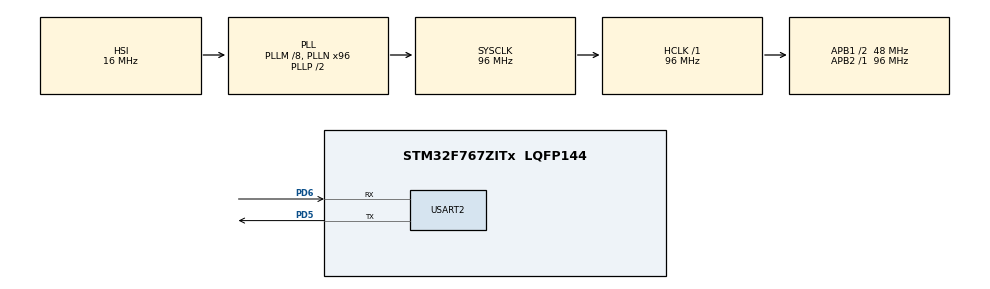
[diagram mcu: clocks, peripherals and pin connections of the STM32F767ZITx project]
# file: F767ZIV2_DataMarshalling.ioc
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FREERTOS.Queues01=msgQueue,16,uint16_t,0,Dynamic,NULL,NULL
FREERTOS.Tasks01=instTask,24,128,instTaskEndPnt,Default,NULL,Dynamic,NULL,NULL;commTask,24,128,commTaskEndPnt,Default,NULL,Dynamic,NULL,NULL
FREERTOS.configUSE_NEWLIB_REENTRANT=1
Mcu.Family=STM32F7
Mcu.Name=STM32F767ZITx
Mcu.Package=LQFP144
NVIC.PriorityGroup=NVIC_PRIORITYGROUP_4
NVIC.TIM1_UP_TIM10_IRQn=true\:15\:0\:false\:false\:true\:false\:false\:true\:true
NVIC.TimeBase=TIM1_UP_TIM10_IRQn
NVIC.TimeBaseIP=TIM1
NVIC.USART2_IRQn=true\:5\:0\:false\:false\:true\:true\:true\:true\:true
PA13.Mode=Serial_Wire
PA13.Signal=SYS_JTMS-SWDIO
PA14.Mode=Serial_Wire
PA14.Signal=SYS_JTCK-SWCLK
PD5.Mode=Asynchronous
PD5.Signal=USART2_TX
PD6.Mode=Asynchronous
PD6.Signal=USART2_RX
PH0/OSC_IN.Mode=HSE-External-Oscillator
PH0/OSC_IN.Signal=RCC_OSC_IN
PH1/OSC_OUT.Mode=HSE-External-Oscillator
PH1/OSC_OUT.Signal=RCC_OSC_OUT
ProjectManager.HeapSize=0x200
ProjectManager.StackSize=0x400
ProjectManager.TargetToolchain=STM32CubeIDE
RCC.AHBFreq_Value=96000000
RCC.APB1CLKDivider=RCC_HCLK_DIV2
RCC.APB1Freq_Value=48000000
RCC.APB1TimFreq_Value=96000000
RCC.APB2Freq_Value=96000000
RCC.APB2TimFreq_Value=96000000
RCC.CortexFreq_Value=96000000
RCC.HCLKFreq_Value=96000000
RCC.HSE_VALUE=25000000
RCC.HSI_VALUE=16000000
RCC.LSE_VALUE=32768
RCC.PLLM=8
RCC.PLLN=96
RCC.SYSCLKFreq_VALUE=96000000
RCC.SYSCLKSource=RCC_SYSCLKSOURCE_PLLCLK
RCC.USBFreq_Value=96000000
RCC.VCOOutputFreq_Value=192000000
USART2.VirtualMode-Asynchronous=VM_ASYNC
VP_FREERTOS_VS_CMSIS_V2.Mode=CMSIS_V2
VP_SYS_VS_tim1.Mode=TIM1
board=custom

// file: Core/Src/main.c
/* USER CODE BEGIN Header */
/**
  ******************************************************************************
  * @file           : main.c
  * @brief          : Main program body
  ******************************************************************************
  * @attention
  *
  * Copyright (c) 2022 STMicroelectronics.
  * All rights reserved.
  *
  * This software is licensed under terms that can be found in the LICENSE file
  * in the root directory of this software component.
  * If no LICENSE file comes with this software, it is provided AS-IS.
  *
  ******************************************************************************
  */
/* USER CODE END Header */
#include "main.h"
#include "cmsis_os.h"

/* USER CODE BEGIN Includes */
#include <time.h>
#include <stdlib.h>
#include <stdio.h>
#include <math.h>
#include <string.h>
#define BUFF_SZ 5
/* USER CODE END Includes */

/* USER CODE BEGIN PTD */
typedef struct {                                // object data type
	uint8_t value;
	uint8_t id;
} SENSOR_MSG_t;
/* USER CODE END PTD */

UART_HandleTypeDef huart2;

/* Definitions for instTask */
osThreadId_t instTaskHandle;
const osThreadAttr_t instTask_attributes = {
  .name = "instTask",
  .stack_size = 128 * 4,
  .priority = (osPriority_t) osPriorityNormal,
};
/* Definitions for commTask */
osThreadId_t commTaskHandle;
const osThreadAttr_t commTask_attributes = {
  .name = "commTask",
  .stack_size = 128 * 4,
  .priority = (osPriority_t) osPriorityNormal,
};
/* Definitions for msgQueue */
osMessageQueueId_t msgQueueHandle;
const osMessageQueueAttr_t msgQueue_attributes = {
  .name = "msgQueue"
};

void SystemClock_Config(void);
static void MX_GPIO_Init(void);
static void MX_USART2_UART_Init(void);
void instTaskEndPnt(void *argument);
void commTaskEndPnt(void *argument);

int main(void)
{

  /* MCU Configuration--------------------------------------------------------*/

  /* Reset of all peripherals, Initializes the Flash interface and the Systick. */
  HAL_Init();

  /* Configure the system clock */
  SystemClock_Config();

  /* Initialize all configured peripherals */
  MX_GPIO_Init();
  MX_USART2_UART_Init();
  /* USER CODE BEGIN 2 */
  uint8_t msg[BUFF_SZ]     = {0};
  HAL_UART_Receive_IT(&huart2, msg, sizeof(msg));
  /* USER CODE END 2 */

  /* Init scheduler */
  osKernelInitialize();

  /* Create the queue(s) */
  /* creation of msgQueue */
  msgQueueHandle = osMessageQueueNew (16, sizeof(uint16_t), &msgQueue_attributes);

  /* Create the thread(s) */
  /* creation of instTask */
  instTaskHandle = osThreadNew(instTaskEndPnt, NULL, &instTask_attributes);

  /* creation of commTask */
  commTaskHandle = osThreadNew(commTaskEndPnt, NULL, &commTask_attributes);

  /* Start scheduler */
  osKernelStart();

  /* We should never get here as control is now taken by the scheduler */
  /* Infinite loop */
  while (1)
  {

  }
}

void SystemClock_Config(void)
{
  RCC_OscInitTypeDef RCC_OscInitStruct = {0};
  RCC_ClkInitTypeDef RCC_ClkInitStruct = {0};

  /** Configure the main internal regulator output voltage
  */
  __HAL_RCC_PWR_CLK_ENABLE();
  __HAL_PWR_VOLTAGESCALING_CONFIG(PWR_REGULATOR_VOLTAGE_SCALE3);

  /** Initializes the RCC Oscillators according to the specified parameters
  * in the RCC_OscInitTypeDef structure.
  */
  RCC_OscInitStruct.OscillatorType = RCC_OSCILLATORTYPE_HSI;
  RCC_OscInitStruct.HSIState = RCC_HSI_ON;
  RCC_OscInitStruct.HSICalibrationValue = RCC_HSICALIBRATION_DEFAULT;
  RCC_OscInitStruct.PLL.PLLState = RCC_PLL_ON;
  RCC_OscInitStruct.PLL.PLLSource = RCC_PLLSOURCE_HSI;
  RCC_OscInitStruct.PLL.PLLM = 8;
  RCC_OscInitStruct.PLL.PLLN = 96;
  RCC_OscInitStruct.PLL.PLLP = RCC_PLLP_DIV2;
  RCC_OscInitStruct.PLL.PLLQ = 2;
  RCC_OscInitStruct.PLL.PLLR = 2;
  if (HAL_RCC_OscConfig(&RCC_OscInitStruct) != HAL_OK)
  {
    Error_Handler();
  }

  /** Activate the Over-Drive mode
  */
  if (HAL_PWREx_EnableOverDrive() != HAL_OK)
  {
    Error_Handler();
  }

  /** Initializes the CPU, AHB and APB buses clocks
  */
  RCC_ClkInitStruct.ClockType = RCC_CLOCKTYPE_HCLK|RCC_CLOCKTYPE_SYSCLK
                              |RCC_CLOCKTYPE_PCLK1|RCC_CLOCKTYPE_PCLK2;
  RCC_ClkInitStruct.SYSCLKSource = RCC_SYSCLKSOURCE_PLLCLK;
  RCC_ClkInitStruct.AHBCLKDivider = RCC_SYSCLK_DIV1;
  RCC_ClkInitStruct.APB1CLKDivider = RCC_HCLK_DIV2;
  RCC_ClkInitStruct.APB2CLKDivider = RCC_HCLK_DIV1;

  if (HAL_RCC_ClockConfig(&RCC_ClkInitStruct, FLASH_LATENCY_3) != HAL_OK)
  {
    Error_Handler();
  }
}

static void MX_USART2_UART_Init(void)
{

  huart2.Instance = USART2;
  huart2.Init.BaudRate = 115200;
  huart2.Init.WordLength = UART_WORDLENGTH_8B;
  huart2.Init.StopBits = UART_STOPBITS_1;
  huart2.Init.Parity = UART_PARITY_NONE;
  huart2.Init.Mode = UART_MODE_TX_RX;
  huart2.Init.HwFlowCtl = UART_HWCONTROL_NONE;
  huart2.Init.OverSampling = UART_OVERSAMPLING_16;
  huart2.Init.OneBitSampling = UART_ONE_BIT_SAMPLE_DISABLE;
  huart2.AdvancedInit.AdvFeatureInit = UART_ADVFEATURE_NO_INIT;
  if (HAL_UART_Init(&huart2) != HAL_OK)
  {
    Error_Handler();
  }

}

static void MX_GPIO_Init(void)
{

  /* GPIO Ports Clock Enable */
  __HAL_RCC_GPIOH_CLK_ENABLE();
  __HAL_RCC_GPIOA_CLK_ENABLE();
  __HAL_RCC_GPIOD_CLK_ENABLE();

}

/* USER CODE BEGIN 4 */
void marshalling(uint8_t value, uint8_t* msg)
{
	uint8_t padding[BUFF_SZ] = {0};
	char padding_character   = '0';

	 // determine the number of digits in the integer
	int l = (value==0)? 1 : log10(value)+1;

	// create the padded message if r is less than BUFF_SZ digits
	sprintf((char *) msg,"%s%i", (char *) memset((uint8_t *)padding, (uint8_t)padding_character, BUFF_SZ - l), value);

}
/* USER CODE END 4 */

void instTaskEndPnt(void *argument)
{
	/* USER CODE BEGIN instTaskEndPnt */
	TickType_t tickCount;
	SENSOR_MSG_t msg;

	/* The cycle time period. The task will be unblocked at time (in ticks)*/
	TickType_t frequency = 3000; //seconds

	/* Get the current tck count */
	tickCount = xTaskGetTickCount();

	// Initiate the random number seed
	srand(time(NULL));

	/* Infinite loop */
	for(;;)
	{
		 // Generate random data
		msg.value  = (uint8_t) (rand() % 10000);
		// The sensor Id
		msg.id     = 0U;

		// Push data onto the message queue
		osMessageQueuePut(msgQueueHandle, &msg, 0U, 1000);

		/* Delay the task execution for a given interval of time. This will make the task
			transition to block state. After the elapse time the task will transition to ready state */
		vTaskDelayUntil( &tickCount, frequency );
	}
	/* USER CODE END instTaskEndPnt */
}

void commTaskEndPnt(void *argument)
{
  /* USER CODE BEGIN commTaskEndPnt */
	TickType_t tickCount;
	SENSOR_MSG_t msg;
	osStatus_t status;
	uint8_t packet[BUFF_SZ]     = {0};

	/* The cycle time period. The task will be unblocked at time (in ticks)*/
	TickType_t frequency = 3000; //seconds

	/* Get the current tck count */
	tickCount = xTaskGetTickCount();

	/* Infinite loop */
	for(;;)
	{
		status = osMessageQueueGet(msgQueueHandle, &msg, NULL, 0U);   // wait for message
		if (status == osOK) {
			marshalling(msg.value, packet);
			HAL_UART_Transmit_IT(&huart2, packet, sizeof(packet));
		}
		/* Delay the task execution for a given interval of time. This will make the task
			transition to block state. After the elapse time the task will transition to ready state */
		vTaskDelayUntil( &tickCount, frequency );
	}
  /* USER CODE END commTaskEndPnt */
}

void HAL_TIM_PeriodElapsedCallback(TIM_HandleTypeDef *htim)
{
  if (htim->Instance == TIM1) {
    HAL_IncTick();
  }
}

void Error_Handler(void)
{
  __disable_irq();
  while (1)
  {
  }
}
